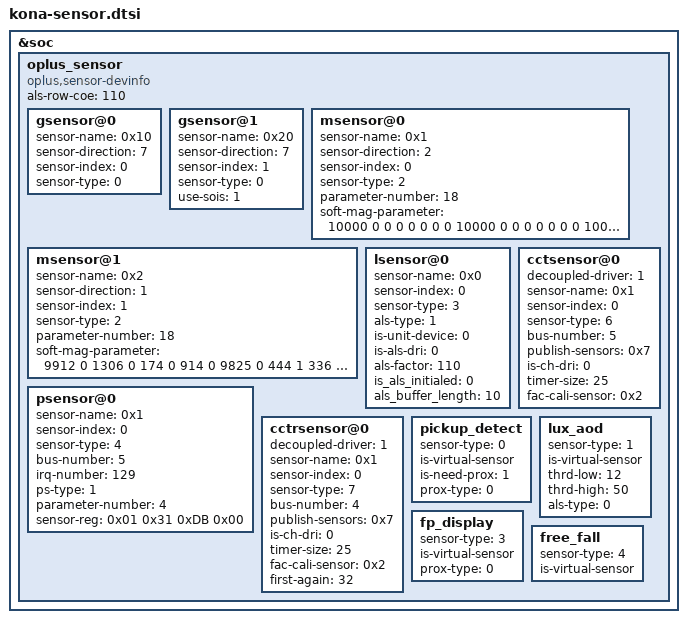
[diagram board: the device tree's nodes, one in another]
&soc {
oplus_sensor {
	compatible = "oplus,sensor-devinfo";
	als-row-coe = <110>;
	/*enum {LSM6DSM = 0x01, BMI160 = 0x02, LSM6DS3 = 0x04};*/
	gsensor@0 {
		sensor-name = <0x10>;//LSM6DSO
		sensor-direction = <7>;
		sensor-index = <0>;//source num
		sensor-type = <0>;//ACCEL
	};
	gsensor@1 {
		sensor-name = <0x20>;//ICM4X6XX
		sensor-direction = <7>;
		sensor-index = <1>;//source num
		sensor-type = <0>;//ACCEL
		use-sois = <1>;   //Use for TDK-sensor, <1>:S-OIS,  <0>:tele ois ic
	};
	/* enum {AKM0991X = 0x01, MMC5603 = 0x02};*/
	msensor@0 {
		sensor-name = <0x1>;//AKM0991X
		sensor-direction = <2>;
		sensor-index = <0>;
		sensor-type = <2>;//MAG
		parameter-number= <18>;
		//sensor-parameter = <2>;//0-useless;other- to differ special parameter
		soft-mag-parameter = <10000 0 0 0 0 0 0 0 10000 0 0 0 0 0 0 0 10000 0>;//e00 sign e01 sign ...
	};
	msensor@1 {
		sensor-name = <0x2>;//MMC5603
		sensor-direction = <1>;
		sensor-index = <1>;
		sensor-type = <2>;//MAG
		parameter-number= <18>;
		soft-mag-parameter = <9912 0 1306 0 174 0 914 0 9825 0 444 1 336 0 482 1 11899 0>;//e00 sign e01 sign ...

	};
	/*enum {STK3A5X=0x01,TCS3701=0x02,TCS3408=0x04};*/
	lsensor@0 {
		sensor-name = <0x0>;//TCS3408
		sensor-index = <0>;
		sensor-type = <3>;//LIGHT
		als-type = <1>;//<1-normal;2-under screen;3-normal needed compensation>
		is-unit-device = <0>;//<1-alsps unit device;0-separate device>
		is-als-dri = <0>;//<0-polling 1-irq>
		als-factor = <110>;
		is_als_initialed = <0>;
		als_buffer_length = <10>;
	};
	psensor@0 {
		sensor-name = <0x1>;//STK33502
		sensor-index = <0>;
		sensor-type = <4>;//PROXIMITY
		bus-number = <5>;
		irq-number = <129>;
		ps-type = <1>;
		parameter-number = <4>;
		sensor-reg = <0x01 0x31
				0xDB 0x00>;

	};
	/* enum {tcs3408 = 0x01  stk37600 = 0x02} */
	cctsensor@0 {
		decoupled-driver = <1>; //0 - tcs3408 driver; 1 - oplus_cct driver
		sensor-name = <0x1>; //tcs3408
		sensor-index = <0>;
		sensor-type = <6>; //CCT
		bus-number = <5>;
		publish-sensors = <0x7>; //bit[0] - als, bit[1] - rgb, bit[2] - flicker
		is-ch-dri = <0>;
		timer-size = <25>; //ms
		fac-cali-sensor = <0x2>; //0x1 - als, 0x2 - rgb, 0x4, flicker
	};
	cctrsensor@0 {
		decoupled-driver = <1>; //0 - tcs3408 driver; 1 - oplus_cct driver
		sensor-name = <0x1>; //tcs3408
		sensor-index = <0>;
		sensor-type = <7>; //CCT_REAR
		bus-number = <4>;
		publish-sensors = <0x7>; //bit[0] - als, bit[1] - rgb, bit[2] - flicker
		is-ch-dri = <0>;
		timer-size = <25>; //ms
		fac-cali-sensor = <0x2>; //0x1 - als, 0x2 - rgb, 0x4, flicker
		first-again = <32>;
	};
	/*virtual sensor
	enum sensor_algo_id {
		PICKUP_DETECT,
		LUX_AOD,
		TP_GESTURE,
		FP_DISPLAY,
		FREE_FALL,
		CAMERA_PROTECT,
		SENSOR_ALGO_NUM
	}*/
	pickup_detect {
		sensor-type = <0>;//PICKUP_DETECT
		is-virtual-sensor;
		is-need-prox = <1>;//0 - disable; 1 - enable
		prox-type = <0>;//prox_type: 0 - proximity; 1 - proximity_fake
	};
	lux_aod {
		sensor-type = <1>; //LUX_AOD
		is-virtual-sensor;
		thrd-low = <12>;
		thrd-high = <50>;
		als-type = <0>; // 0 - ambient_light; 1 - wise_light
	};
	fp_display {
		sensor-type = <3>;//FP_DISPLAY
		is-virtual-sensor;
		prox-type = <0>; //  0 - proximity; 1 - proximity_fake
	};
	free_fall {
		sensor-type = <4>;//FREE_FALL
		is-virtual-sensor;
	};
};
};
